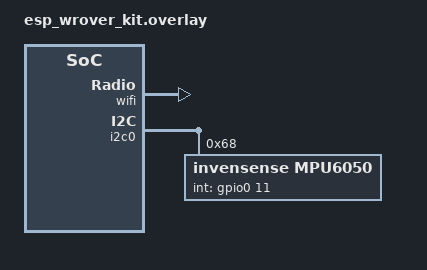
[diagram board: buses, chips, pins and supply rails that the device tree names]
/*
 * (C) Copyright 2024, SECO Mind Srl
 *
 * SPDX-License-Identifier: Apache-2.0
 */

&wifi {
	status = "okay";
};

&i2c0 {
	mpu6050@68 {
		compatible = "invensense,mpu6050";
		reg = <0x68>;
		status = "okay";
		int-gpios = <&gpio0 11 GPIO_ACTIVE_HIGH>;
	};
};
